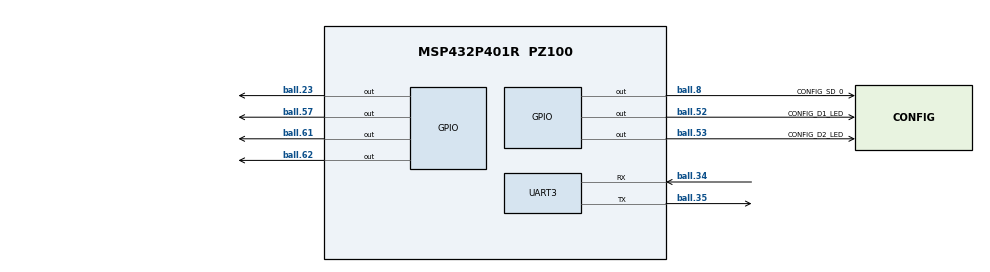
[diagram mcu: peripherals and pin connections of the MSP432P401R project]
/**
 * @cliArgs --device "MSP432P401R" --package "PZ100" --part "Default" --product "simplelink_msp432p4_sdk@3.40.01.02"
 * @versions {"tool":"1.11.0+2225"}
 */

/**
 * Import the modules used in this configuration.
 */
const GPIO      = scripting.addModule("/ti/drivers/GPIO", {}, false);
const GPIO1     = GPIO.addInstance();
const GPIO2     = GPIO.addInstance();
const GPIO3     = GPIO.addInstance();
const GPIO4     = GPIO.addInstance();
const GPIO5     = GPIO.addInstance();
const GPIO6     = GPIO.addInstance();
const I2C       = scripting.addModule("/ti/drivers/I2C", {}, false);
const I2C1      = I2C.addInstance();
const I2C2      = I2C.addInstance();
const Power     = scripting.addModule("/ti/drivers/Power");
const RTOS      = scripting.addModule("/ti/drivers/RTOS");
const SD        = scripting.addModule("/ti/drivers/SD", {}, false);
const SD1       = SD.addInstance();
const SPI       = scripting.addModule("/ti/drivers/SPI", {}, false);
const SPI1      = SPI.addInstance();
const UART      = scripting.addModule("/ti/drivers/UART", {}, false);
const UART1     = UART.addInstance();
const UART2     = UART.addInstance();
const UART3     = UART.addInstance();
const Watchdog  = scripting.addModule("/ti/drivers/Watchdog", {}, false);
const Watchdog1 = Watchdog.addInstance();

/**
 * Write custom configuration values to the imported modules.
 */
GPIO1.$name           = "CONFIG_GPIO_SIM_PWRKEY";
GPIO1.gpioPin.$assign = "ball.57";

GPIO2.$name           = "CONFIG_GPIO_SIM_RST";
GPIO2.gpioPin.$assign = "ball.62";

GPIO3.$name           = "CONFIG_GPIO_RADAR_PMIC_EN";
GPIO3.gpioPin.$assign = "ball.23";

GPIO4.$name           = "CONFIG_GPIO0_BTN";
GPIO4.gpioPin.$assign = "ball.61";

GPIO5.$name           = "CONFIG_D1_LED";
GPIO5.gpioPin.$assign = "ball.52";

GPIO6.$name           = "CONFIG_D2_LED";
GPIO6.gpioPin.$assign = "ball.53";

I2C1.$name = "CONFIG_I2C_0";

I2C2.$name = "CONFIG_I2C_1";

Power.performanceLevel3.$name = "ti_drivers_power_PowerMSP432PerfLevels0";
Power.performanceLevel2.$name = "ti_drivers_power_PowerMSP432PerfLevels1";
Power.performanceLevel1.$name = "ti_drivers_power_PowerMSP432PerfLevels2";
Power.performanceLevel0.$name = "ti_drivers_power_PowerMSP432PerfLevels3";


SD1.$name                       = "CONFIG_SD_0";
SD1.useFatFS                    = true;
SD1.slaveSelect.$name           = "CONFIG_SD_GPIO";
SD1.slaveSelect.gpioPin.$assign = "ball.8";

SD1.spiInstance  = SPI1;
SPI1.$name       = "CONFIG_SD_SPI";
SPI1.spi.$assign = "EUSCI_B0";

UART1.$name = "CONFIG_CLI_UART";

UART2.baudRates    = [1200,2400,4800,9600,19200,38400,57600,115200,230400,460800,921600];
UART2.$name        = "CONFIG_SIM_UART";
UART2.uart.$assign = "EUSCI_A3";

UART3.$name              = "CONFIG_SENSOR_UART";
UART3.uart.$assign       = "EUSCI_A2";
UART3.uart.txPin.$assign = "ball.35";
UART3.uart.rxPin.$assign = "ball.34";

Watchdog1.$name  = "CONFIG_WATCHDOG_0";
Watchdog1.period = 16000;

/**
 * Pinmux solution for unlocked pins/peripherals. This ensures that minor changes to the automatic solver in a future
 * version of the tool will not impact the pinmux you originally saw.  These lines can be completely deleted in order to
 * re-solve from scratch.
 */
I2C1.i2c.$suggestSolution                    = "EUSCI_B2";
I2C1.i2c.sdaPin.$suggestSolution             = "ball.17";
I2C1.i2c.sclPin.$suggestSolution             = "ball.16";
I2C2.i2c.$suggestSolution                    = "EUSCI_B1";
I2C2.i2c.sdaPin.$suggestSolution             = "ball.78";
I2C2.i2c.sclPin.$suggestSolution             = "ball.79";
RTOS.timer0.resource.$suggestSolution        = "Timer_A0";
SPI1.spi.sclkPin.$suggestSolution            = "ball.9";
SPI1.spi.misoPin.$suggestSolution            = "ball.11";
SPI1.spi.mosiPin.$suggestSolution            = "ball.10";
SPI1.spi.dmaRxChannel.$suggestSolution       = "DMA_CH1";
SPI1.spi.dmaTxChannel.$suggestSolution       = "DMA_CH0";
SPI1.spi.dmaInterruptNumber.$suggestSolution = "DMA_INT0";
UART1.uart.$suggestSolution                  = "EUSCI_A0";
UART1.uart.txPin.$suggestSolution            = "ball.7";
UART1.uart.rxPin.$suggestSolution            = "ball.6";
UART2.uart.txPin.$suggestSolution            = "ball.99";
UART2.uart.rxPin.$suggestSolution            = "ball.98";
Watchdog1.watchdog.$suggestSolution          = "WATCHDOG";
